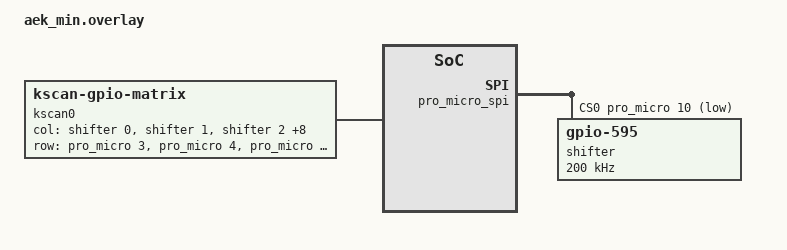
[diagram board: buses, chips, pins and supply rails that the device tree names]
&pro_micro_spi {
	status = "okay";
	cs-gpios = <&pro_micro 10 GPIO_ACTIVE_LOW>; /*CS*/
	shifter: 595@0 {
		compatible = "zmk,gpio-595";
		status = "okay";
		gpio-controller;
		spi-max-frequency = <200000>;
		reg = <0>;
        #gpio-cells = <2>;
		ngpios = <8>;
	};
};


/ {
    chosen {
        zmk,kscan = &kscan0;
    };

    kscan0: kscan_0 {
        compatible = "zmk,kscan-gpio-matrix";
        diode-direction = "col2row";
        wakeup-source;

        col-gpios =
            <&shifter 0 GPIO_ACTIVE_HIGH>,
            <&shifter 1 GPIO_ACTIVE_HIGH>,
            <&shifter 2 GPIO_ACTIVE_HIGH>,
            <&pro_micro 1 GPIO_ACTIVE_HIGH>,
            <&pro_micro 0 GPIO_ACTIVE_HIGH>,
            <&pro_micro 2 GPIO_ACTIVE_HIGH>,
            <&pro_micro 18 GPIO_ACTIVE_HIGH>,
            <&shifter 3 GPIO_ACTIVE_HIGH>,
            <&shifter 4 GPIO_ACTIVE_HIGH>,
            <&shifter 5 GPIO_ACTIVE_HIGH>,
            <&shifter 6 GPIO_ACTIVE_HIGH>;

        row-gpios =
            <&pro_micro 3  (GPIO_ACTIVE_HIGH | GPIO_PULL_DOWN)>,
            <&pro_micro 4  (GPIO_ACTIVE_HIGH | GPIO_PULL_DOWN)>,
            <&pro_micro 21  (GPIO_ACTIVE_HIGH | GPIO_PULL_DOWN)>,
            <&pro_micro 20  (GPIO_ACTIVE_HIGH | GPIO_PULL_DOWN)>,
            <&pro_micro 19  (GPIO_ACTIVE_HIGH | GPIO_PULL_DOWN)>,
            <&pro_micro 14  (GPIO_ACTIVE_HIGH | GPIO_PULL_DOWN)>,
            <&pro_micro 9  (GPIO_ACTIVE_HIGH | GPIO_PULL_DOWN)>,
            <&pro_micro 8  (GPIO_ACTIVE_HIGH | GPIO_PULL_DOWN)>,
            <&pro_micro 7  (GPIO_ACTIVE_HIGH | GPIO_PULL_DOWN)>,
            <&pro_micro 6  (GPIO_ACTIVE_HIGH | GPIO_PULL_DOWN)>,
            <&pro_micro 5 (GPIO_ACTIVE_HIGH | GPIO_PULL_DOWN)>;
    };
};
